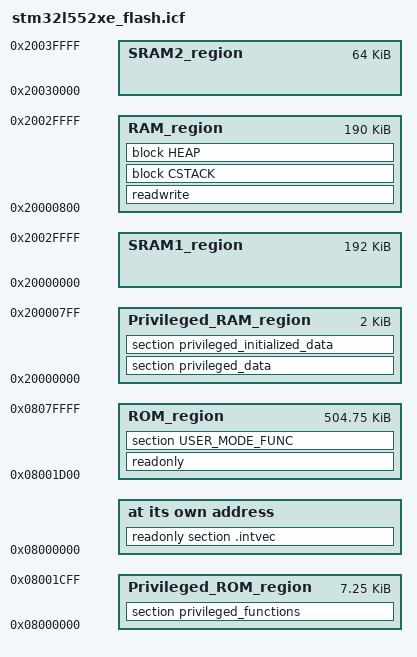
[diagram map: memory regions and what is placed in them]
/*###ICF### Section handled by ICF editor, don't touch! ****/
/*-Editor annotation file-*/
/* IcfEditorFile="$TOOLKIT_DIR$\config\ide\IcfEditor\cortex_v1_0.xml" */
/*-Specials-*/
define symbol __ICFEDIT_intvec_start__ = 0x08000000;
/*-Memory Regions-*/
define symbol __ICFEDIT_region_ROM_start__            = 0x08001D00;
define symbol __ICFEDIT_region_ROM_end__              = 0x0807FFFF;
define symbol __ICFEDIT_region_Privileged_ROM_start__ = 0x08000000;
define symbol __ICFEDIT_region_Privileged_ROM_end__   = 0x08001CFF;
define symbol __ICFEDIT_region_RAM_start__            = 0x20000800;
define symbol __ICFEDIT_region_RAM_end__              = 0x2002FFFF;
define symbol __ICFEDIT_region_Privileged_RAM_start__ = 0x20000000;
define symbol __ICFEDIT_region_Privileged_RAM_end__   = 0x200007FF;

/*-Sizes-*/
define symbol __ICFEDIT_size_cstack__ = 0x400;
define symbol __ICFEDIT_size_heap__   = 0x200;
/**** End of ICF editor section. ###ICF###*/

define symbol __region_SRAM1_start__  = 0x20000000;
define symbol __region_SRAM1_end__    = 0x2002FFFF;
define symbol __region_SRAM2_start__  = 0x20030000;
define symbol __region_SRAM2_end__    = 0x2003FFFF;

/*------------- START:  FreeRTOS MPU symbols ------------**/

define symbol __FLASH_segment_start__        =  0x08000000;
define symbol __FLASH_segment_end__          =  0x0807FFFF;
define symbol __privileged_functions_start__ =  0x08000000;
define symbol __privileged_functions_end__   =  0x08001CFF;
define symbol __syscalls_flash_start__       =  0x08001D00;
define symbol __syscalls_flash_end__         =  0x08001EFF;
define symbol __unprivileged_flash_start__   =  0x08001F00;
define symbol __unprivileged_flash_end__     =  0x0807FFFF;
define symbol __SRAM_segment_start__         =  0x20000000;
define symbol __SRAM_segment_end__           =  0x2003FFFF;
define symbol __privileged_sram_start__      =  0x20000000;
define symbol __privileged_sram_end__        =  0x200007FF;
define symbol __unprivileged_sram_start__    =  0x20000800;
define symbol __unprivileged_sram_end__      =  0x2002FFFF;

export symbol __FLASH_segment_start__;
export symbol __FLASH_segment_end__;
export symbol __privileged_functions_start__;
export symbol __privileged_functions_end__;
export symbol __syscalls_flash_start__;
export symbol __syscalls_flash_end__;
export symbol __unprivileged_flash_start__;
export symbol __unprivileged_flash_end__;
export symbol __SRAM_segment_start__;
export symbol __SRAM_segment_end__;
export symbol __privileged_sram_start__;
export symbol __privileged_sram_end__;
export symbol __unprivileged_sram_start__;
export symbol __unprivileged_sram_end__;


/*-------------  END: FreeRTOS MPU symbols ------------**/

define memory mem with size = 4G;
define region ROM_region      = mem:[from __ICFEDIT_region_ROM_start__   to __ICFEDIT_region_ROM_end__];
define region Privileged_ROM_region      = mem:[from __ICFEDIT_region_Privileged_ROM_start__   to __ICFEDIT_region_Privileged_ROM_end__];
define region RAM_region      = mem:[from __ICFEDIT_region_RAM_start__   to __ICFEDIT_region_RAM_end__];
define region Privileged_RAM_region      = mem:[from __ICFEDIT_region_Privileged_RAM_start__   to __ICFEDIT_region_Privileged_RAM_end__];
define region SRAM1_region    = mem:[from __region_SRAM1_start__   to __region_SRAM1_end__];
define region SRAM2_region    = mem:[from __region_SRAM2_start__   to __region_SRAM2_end__];

define block CSTACK    with alignment = 8, size = __ICFEDIT_size_cstack__   { };
define block HEAP      with alignment = 8, size = __ICFEDIT_size_heap__     { };

initialize by copy { readwrite };
do not initialize  { section .noinit };

place at address mem:__ICFEDIT_intvec_start__ { readonly section .intvec };

place in ROM_region   { readonly, section USER_MODE_FUNC };
place in RAM_region   { readwrite,
                        block CSTACK, block HEAP };
place in Privileged_ROM_region   {section privileged_functions };
place in Privileged_RAM_region   {section privileged_data, section privileged_initialized_data};

place in SRAM1_region { };
place in SRAM2_region { };
